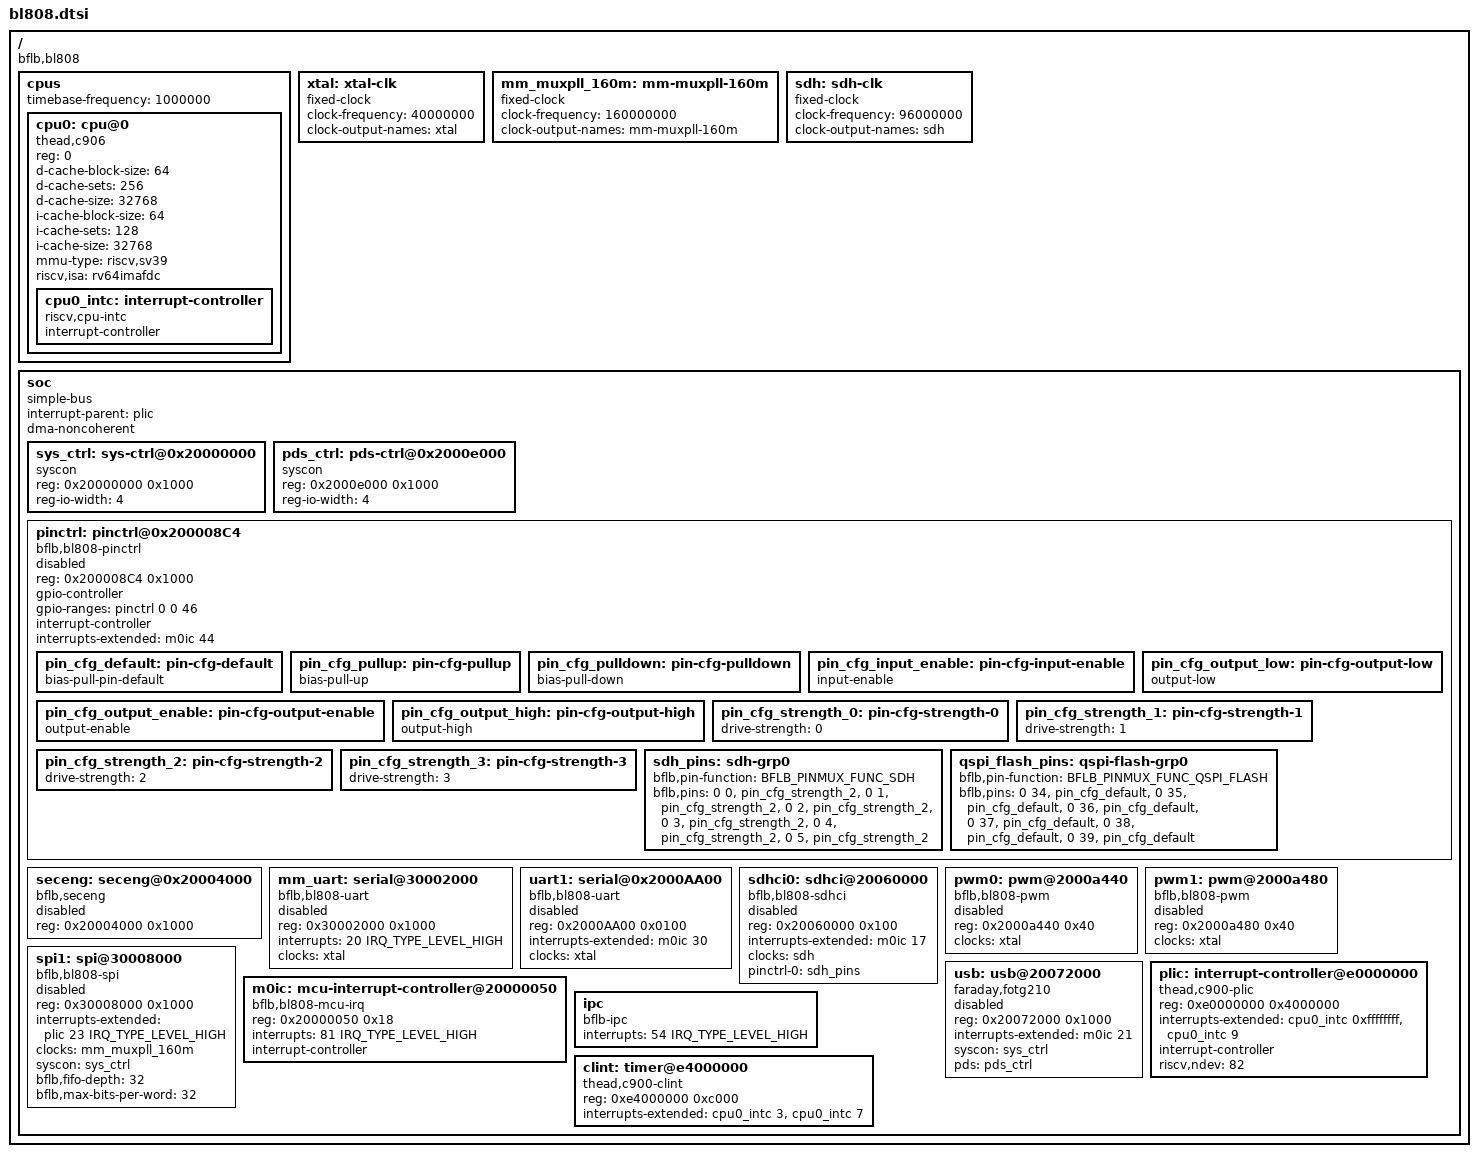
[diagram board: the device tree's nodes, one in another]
// SPDX-License-Identifier: (GPL-2.0+ or MIT)
/*
 * Copyright (C) 2023 Bouffalo Lab
 */

#include <dt-bindings/interrupt-controller/irq.h>
#include <dt-bindings/mailbox/bflb-ipc.h>
#include <dt-bindings/pinctrl/pinctrl-bflb.h>

/ {
	compatible = "bflb,bl808";
	#address-cells = <1>;
	#size-cells = <1>;

	cpus {
		timebase-frequency = <1000000>;
		#address-cells = <1>;
		#size-cells = <0>;

		cpu0: cpu@0 {
			compatible = "thead,c906", "riscv";
			device_type = "cpu";
			reg = <0>;
			d-cache-block-size = <64>;
			d-cache-sets = <256>;
			d-cache-size = <32768>;
			i-cache-block-size = <64>;
			i-cache-sets = <128>;
			i-cache-size = <32768>;
			mmu-type = "riscv,sv39";
			riscv,isa = "rv64imafdc";

			cpu0_intc: interrupt-controller {
				compatible = "riscv,cpu-intc";
				interrupt-controller;
				#address-cells = <0>;
				#interrupt-cells = <1>;
			};
		};
	};

	xtal: xtal-clk {
		compatible = "fixed-clock";
		clock-frequency = <40000000>;
		clock-output-names = "xtal";
		#clock-cells = <0>;
	};

	mm_muxpll_160m: mm-muxpll-160m {
		compatible = "fixed-clock";
		clock-frequency = <160000000>;
		clock-output-names = "mm-muxpll-160m";
		#clock-cells = <0>;
	};

	sdh: sdh-clk {
		compatible = "fixed-clock";
		clock-frequency = <96000000>;
		clock-output-names = "sdh";
		#clock-cells = <0>;
	};

	soc {
		compatible = "simple-bus";
		ranges;
		interrupt-parent = <&plic>;
		dma-noncoherent;
		#address-cells = <1>;
		#size-cells = <1>;

		sys_ctrl: sys-ctrl@0x20000000 {
			compatible = "syscon";
			reg = <0x20000000 0x1000>;
			status = "okay";
			reg-io-width = <4>;
		};

		pds_ctrl: pds-ctrl@0x2000e000 {
			compatible = "syscon";
			reg = <0x2000e000 0x1000>;
			status = "okay";
			reg-io-width = <4>;
		};

		pinctrl: pinctrl@0x200008C4 {
			compatible = "bflb,bl808-pinctrl";
			reg = <0x200008C4 0x1000>;
			//clocks = <&gpio_clk>;
			status = "disabled";

			gpio-controller;
			#gpio-cells = <2>;
			gpio-ranges = <&pinctrl 0 0 46>;

			interrupt-controller;
			#interrupt-cells = <2>;
			interrupts-extended = <&m0ic 44>;

			/*
			 * developers should define their own pin config nodes with
			 * multiple properties if the requirements are not met using
			 * the following basic ones.
			 */
			pin_cfg_default: pin-cfg-default {
				bias-pull-pin-default;
			};

			pin_cfg_pullup: pin-cfg-pullup {
				bias-pull-up;
			};

			pin_cfg_pulldown: pin-cfg-pulldown {
				bias-pull-down;
			};

			pin_cfg_input_enable: pin-cfg-input-enable {
				input-enable;
			};

			pin_cfg_output_enable: pin-cfg-output-enable {
				output-enable;
			};

			pin_cfg_output_high: pin-cfg-output-high {
				output-high;
			};

			pin_cfg_output_low: pin-cfg-output-low {
				output-low;
			};

			pin_cfg_strength_0: pin-cfg-strength-0 {
				drive-strength = <0>;
			};

			pin_cfg_strength_1: pin-cfg-strength-1 {
				drive-strength = <1>;
			};

			pin_cfg_strength_2: pin-cfg-strength-2 {
				drive-strength = <2>;
			};

			pin_cfg_strength_3: pin-cfg-strength-3 {
				drive-strength = <3>;
			};

			sdh_pins: sdh-grp0 {
				bflb,pin-function = <BFLB_PINMUX_FUNC_SDH>;
				bflb,pins = <0 0 &pin_cfg_strength_2>,
							<0 1 &pin_cfg_strength_2>,
							<0 2 &pin_cfg_strength_2>,
							<0 3 &pin_cfg_strength_2>,
							<0 4 &pin_cfg_strength_2>,
							<0 5 &pin_cfg_strength_2>;
			};

			qspi_flash_pins: qspi-flash-grp0 {
				bflb,pin-function = <BFLB_PINMUX_FUNC_QSPI_FLASH>;
				bflb,pins = <0 34 &pin_cfg_default>,
							<0 35 &pin_cfg_default>,
							<0 36 &pin_cfg_default>,
							<0 37 &pin_cfg_default>,
							<0 38 &pin_cfg_default>,
							<0 39 &pin_cfg_default>;
			};
		};

		seceng: seceng@0x20004000 {
			compatible = "bflb,seceng";
			reg = <0x20004000 0x1000>;
			status = "disabled";
		};

		mm_uart: serial@30002000 {
			compatible = "bflb,bl808-uart";
			reg = <0x30002000 0x1000>;
			interrupts = <20 IRQ_TYPE_LEVEL_HIGH>;
			clocks = <&xtal>;
			status = "disabled";
		};

		uart1: serial@0x2000AA00 {
			compatible = "bflb,bl808-uart";
			reg = <0x2000AA00 0x0100>;
			interrupts-extended = <&m0ic 30>;
			clocks = <&xtal>;
			status = "disabled";
		};

		sdhci0: sdhci@20060000 {
			compatible = "bflb,bl808-sdhci";
			reg = <0x20060000 0x100>;
			interrupts-extended = <&m0ic 17>;
			clocks = <&sdh>;
			status = "disabled";
			pinctrl-names = "default";
			pinctrl-0 = <&sdh_pins>;
		};

		pwm0: pwm@2000a440 {
			compatible = "bflb,bl808-pwm";
			reg = <0x2000a440 0x40>;
			clocks = <&xtal>;
			#pwm-cells = <3>;
			status = "disabled";
		};

		pwm1: pwm@2000a480 {
			compatible = "bflb,bl808-pwm";
			reg = <0x2000a480 0x40>;
			clocks = <&xtal>;
			#pwm-cells = <3>;
			status = "disabled";
		};

		spi1: spi@30008000 {
			compatible = "bflb,bl808-spi";
			reg = <0x30008000 0x1000>;
			interrupts-extended = <&plic 23 IRQ_TYPE_LEVEL_HIGH>;
			clocks = <&mm_muxpll_160m>;
			#address-cells = <1>;
			#size-cells = <0>;
			syscon = <&sys_ctrl>;
			bflb,fifo-depth = <32>;
			bflb,max-bits-per-word = <32>;
			status = "disabled";
		};

		usb: usb@20072000 {
			compatible = "faraday,fotg210", "bflb,bl808-usb";
			reg = <0x20072000 0x1000>;
			interrupts-extended = <&m0ic 21>;
			syscon = <&sys_ctrl>;
			pds = <&pds_ctrl>;
			status = "disabled";
		};
		/*
		ipclic: mailbox@30005000 {
			compatible = "bflb,bl808-ipc";
			reg = <0x30005000 0x20>,
			      <0x30005020 0x20>,
			      <0x2000a800 0x20>,
			      <0x2000a820 0x20>;
			interrupts = <54 IRQ_TYPE_LEVEL_HIGH>;
			interrupt-controller;
			#interrupt-cells = <3>;
			#mbox-cells = <2>;
			status = "disabled";
		};
		*/

		m0ic: mcu-interrupt-controller@20000050 {
			compatible = "bflb,bl808-mcu-irq";
			reg = <0x20000050 0x18>;
			interrupts = <81 IRQ_TYPE_LEVEL_HIGH>;
			interrupt-controller;
			#address-cells = <0>;
			#interrupt-cells = <1>;
		};

		plic: interrupt-controller@e0000000 {
			compatible = "thead,c900-plic";
			reg = <0xe0000000 0x4000000>;
			interrupts-extended = <&cpu0_intc 0xffffffff>,
					      <&cpu0_intc 9>;
			interrupt-controller;
			#address-cells = <0>;
			#interrupt-cells = <2>;
			riscv,ndev = <82>;
			status = "okay";
		};

		ipc {
			compatible = "bflb-ipc";
			interrupts = <54 IRQ_TYPE_LEVEL_HIGH>; /* IPC #54 */
			status = "okay";
		};

		clint: timer@e4000000 {
			compatible = "thead,c900-clint";
			reg = <0xe4000000 0xc000>;
			interrupts-extended = <&cpu0_intc 3>,
					      <&cpu0_intc 7>;
		};
	};
};
